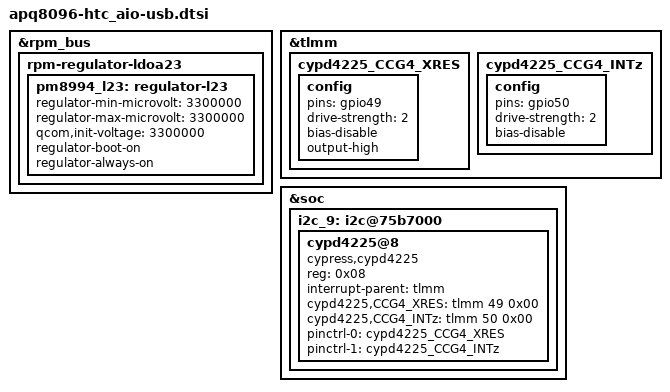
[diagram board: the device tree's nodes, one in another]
&rpm_bus {
	rpm-regulator-ldoa23 {
		status = "okay";
		pm8994_l23: regulator-l23 {
			regulator-min-microvolt = <3300000>;
			regulator-max-microvolt = <3300000>;
			qcom,init-voltage = <3300000>;
			status = "okay";
			regulator-boot-on;
			regulator-always-on;
		};
	};
};

&tlmm {
    cypd4225_CCG4_XRES: cypd4225_CCG4_XRES {
        config {
            pins = "gpio49";
            drive-strength = <2>;
            bias-disable;
            output-high;
        };
    };

    cypd4225_CCG4_INTz: cypd4225_CCG4_INTz {
        config {
            pins = "gpio50";
            drive-strength = <2>;
            bias-disable;
        };
    };
};

&soc {
	i2c_9: i2c@75b7000 { /* BLSP9 */
        cypd4225@8 {
            compatible = "cypress,cypd4225";
                       reg = <0x08>;
            interrupt-parent = <&tlmm>;
            cypd4225,CCG4_XRES = <&tlmm 49 0x00>;
            cypd4225,CCG4_INTz = <&tlmm 50 0x00>;

            pinctrl-names = "cypd4225_CCG4_XRES", "cypd4225_CCG4_INTz";
            pinctrl-0 = <&cypd4225_CCG4_XRES>;
            pinctrl-1 = <&cypd4225_CCG4_INTz>;
        };
    };
};
